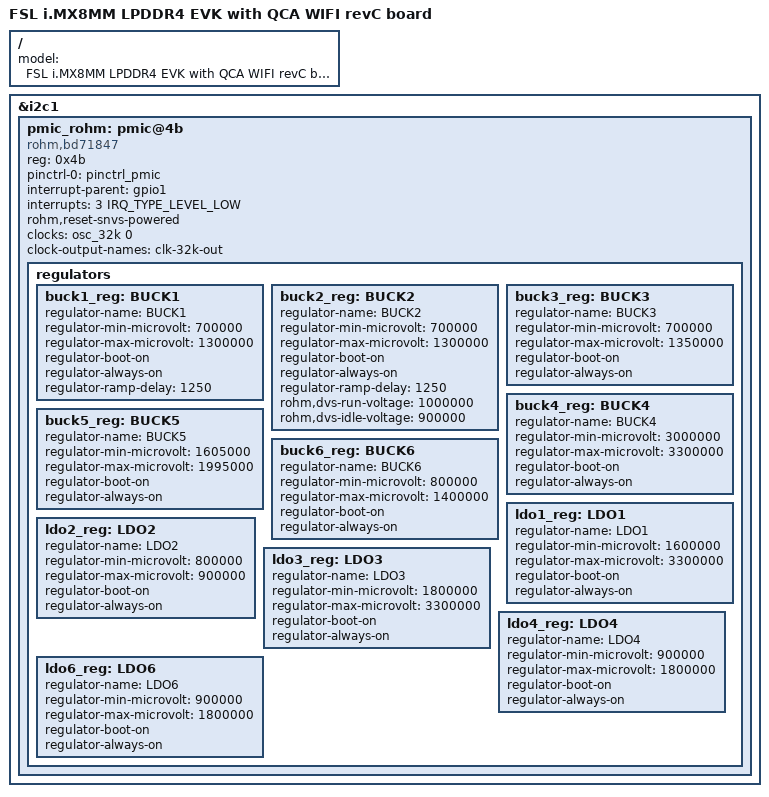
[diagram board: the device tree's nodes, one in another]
// SPDX-License-Identifier: (GPL-2.0+ OR MIT)
/*
 * Copyright 2019 NXP
 */

/dts-v1/;

#include "imx8mm-evk.dts"

/ {
	model = "FSL i.MX8MM LPDDR4 EVK with QCA WIFI revC board ";
};

/delete-node/&pmic_nxp;

&i2c1 {
	pmic_rohm: pmic@4b {
		compatible = "rohm,bd71847";
		reg = <0x4b>;
		pinctrl-0 = <&pinctrl_pmic>;
		pinctrl-names = "default";
		interrupt-parent = <&gpio1>;
		interrupts = <3 IRQ_TYPE_LEVEL_LOW>;
		rohm,reset-snvs-powered;

		#clock-cells = <0>;
		clocks = <&osc_32k 0>;
		clock-output-names = "clk-32k-out";

		regulators {
			buck1_reg: BUCK1 {
				regulator-name = "BUCK1";
				regulator-min-microvolt = <700000>;
				regulator-max-microvolt = <1300000>;
				regulator-boot-on;
				regulator-always-on;
				regulator-ramp-delay = <1250>;
			};

			buck2_reg: BUCK2 {
				regulator-name = "BUCK2";
				regulator-min-microvolt = <700000>;
				regulator-max-microvolt = <1300000>;
				regulator-boot-on;
				regulator-always-on;
				regulator-ramp-delay = <1250>;
				rohm,dvs-run-voltage = <1000000>;
				rohm,dvs-idle-voltage = <900000>;
			};

			buck3_reg: BUCK3 {
				// BUCK5 in datasheet
				regulator-name = "BUCK3";
				regulator-min-microvolt = <700000>;
				regulator-max-microvolt = <1350000>;
				regulator-boot-on;
				regulator-always-on;
			};

			buck4_reg: BUCK4 {
				// BUCK6 in datasheet
				regulator-name = "BUCK4";
				regulator-min-microvolt = <3000000>;
				regulator-max-microvolt = <3300000>;
				regulator-boot-on;
				regulator-always-on;
			};

			buck5_reg: BUCK5 {
				// BUCK7 in datasheet
				regulator-name = "BUCK5";
				regulator-min-microvolt = <1605000>;
				regulator-max-microvolt = <1995000>;
				regulator-boot-on;
				regulator-always-on;
			};

			buck6_reg: BUCK6 {
				// BUCK8 in datasheet
				regulator-name = "BUCK6";
				regulator-min-microvolt = <800000>;
				regulator-max-microvolt = <1400000>;
				regulator-boot-on;
				regulator-always-on;
			};

			ldo1_reg: LDO1 {
				regulator-name = "LDO1";
				regulator-min-microvolt = <1600000>;
				regulator-max-microvolt = <3300000>;
				regulator-boot-on;
				regulator-always-on;
			};

			ldo2_reg: LDO2 {
				regulator-name = "LDO2";
				regulator-min-microvolt = <800000>;
				regulator-max-microvolt = <900000>;
				regulator-boot-on;
				regulator-always-on;
			};

			ldo3_reg: LDO3 {
				regulator-name = "LDO3";
				regulator-min-microvolt = <1800000>;
				regulator-max-microvolt = <3300000>;
				regulator-boot-on;
				regulator-always-on;
			};

			ldo4_reg: LDO4 {
				regulator-name = "LDO4";
				regulator-min-microvolt = <900000>;
				regulator-max-microvolt = <1800000>;
				regulator-boot-on;
				regulator-always-on;
			};

			ldo6_reg: LDO6 {
				regulator-name = "LDO6";
				regulator-min-microvolt = <900000>;
				regulator-max-microvolt = <1800000>;
				regulator-boot-on;
				regulator-always-on;
			};
		};
	};
};
